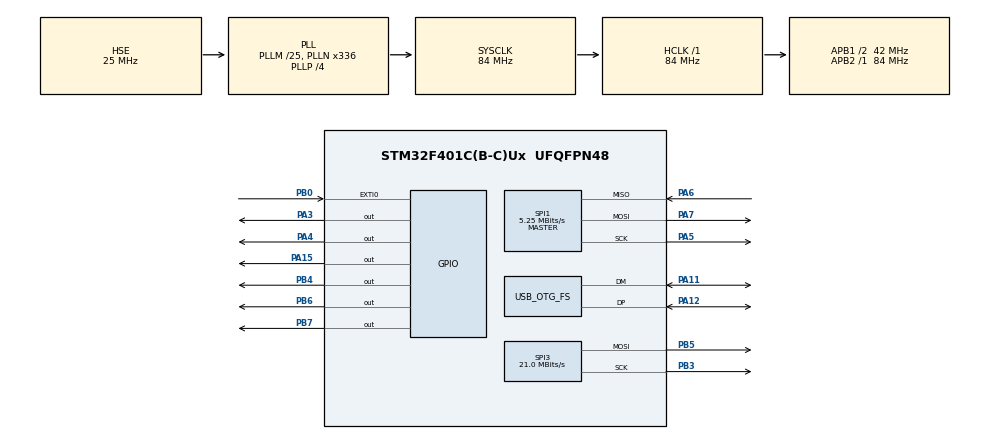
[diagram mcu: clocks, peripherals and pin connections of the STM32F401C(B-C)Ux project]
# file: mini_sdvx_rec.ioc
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AL94.I-CUBE-USBD-COMPOSITE.1.0.3.CompositeCcUSBJjCOMPOSITEJjCDCIiACM=true
AL94.I-CUBE-USBD-COMPOSITE.1.0.3.CompositeCcUSBJjCOMPOSITEJjCOMPOSITE=true
AL94.I-CUBE-USBD-COMPOSITE.1.0.3.CompositeCcUSBJjCOMPOSITEJjCore=true
AL94.I-CUBE-USBD-COMPOSITE.1.0.3.CompositeCcUSBJjCOMPOSITEJjHIDIiKEYBOARD=true
AL94.I-CUBE-USBD-COMPOSITE.1.0.3.CompositeCcUSBJjCOMPOSITEJjHIDIiMOUSE=true
AL94.I-CUBE-USBD-COMPOSITE.1.0.3._USBD_USE_CDC_ACM=true
AL94.I-CUBE-USBD-COMPOSITE.1.0.3._USBD_USE_DFU=false
AL94.I-CUBE-USBD-COMPOSITE.1.0.3._USBD_USE_HID_KEYBOARD=true
AL94.I-CUBE-USBD-COMPOSITE.1.0.3._USBD_USE_HID_MOUSE=true
AL94.I-CUBE-USBD-COMPOSITE.1.0.3._USBD_USE_HS=false
Mcu.Family=STM32F4
Mcu.Name=STM32F401C(B-C)Ux
Mcu.Package=UFQFPN48
NVIC.EXTI0_IRQn=true\:0\:0\:false\:false\:true\:true\:true\:true
NVIC.OTG_FS_IRQn=true\:0\:0\:false\:false\:true\:true\:true\:true
NVIC.PriorityGroup=NVIC_PRIORITYGROUP_4
PA11.Mode=Device_Only
PA11.Signal=USB_OTG_FS_DM
PA12.Mode=Device_Only
PA12.Signal=USB_OTG_FS_DP
PA13.Mode=Serial_Wire
PA13.Signal=SYS_JTMS-SWDIO
PA14.Mode=Serial_Wire
PA14.Signal=SYS_JTCK-SWCLK
PA15.Signal=GPIO_Output
PA3.GPIO_Speed=GPIO_SPEED_FREQ_HIGH
PA3.Signal=GPIO_Output
PA4.GPIO_Speed=GPIO_SPEED_FREQ_HIGH
PA4.PinState=GPIO_PIN_SET
PA4.Signal=GPIO_Output
PA5.Mode=Full_Duplex_Master
PA5.Signal=SPI1_SCK
PA6.Mode=Full_Duplex_Master
PA6.Signal=SPI1_MISO
PA7.Mode=Full_Duplex_Master
PA7.Signal=SPI1_MOSI
PB0.GPIO_ModeDefaultEXTI=GPIO_MODE_IT_FALLING
PB0.GPIO_PuPd=GPIO_PULLUP
PB0.Signal=GPXTI0
PB3.Mode=TX_Only_Simplex_Unidirect_Master
PB3.Signal=SPI3_SCK
PB4.Signal=GPIO_Output
PB5.Mode=TX_Only_Simplex_Unidirect_Master
PB5.Signal=SPI3_MOSI
PB6.Signal=GPIO_Output
PB7.Signal=GPIO_Output
PH0\ -\ OSC_IN.Mode=HSE-External-Oscillator
PH0\ -\ OSC_IN.Signal=RCC_OSC_IN
PH1\ -\ OSC_OUT.Mode=HSE-External-Oscillator
PH1\ -\ OSC_OUT.Signal=RCC_OSC_OUT
ProjectManager.HeapSize=0x400
ProjectManager.StackSize=0x600
ProjectManager.TargetToolchain=MDK-ARM V5.32
RCC.48MHZClocksFreq_Value=48000000
RCC.AHBFreq_Value=84000000
RCC.APB1CLKDivider=RCC_HCLK_DIV2
RCC.APB1Freq_Value=42000000
RCC.APB1TimFreq_Value=84000000
RCC.APB2Freq_Value=84000000
RCC.APB2TimFreq_Value=84000000
RCC.CortexFreq_Value=84000000
RCC.HCLKFreq_Value=84000000
RCC.HSE_VALUE=25000000
RCC.HSI_VALUE=16000000
RCC.LSE_VALUE=32768
RCC.PLLM=25
RCC.PLLN=336
RCC.PLLP=RCC_PLLP_DIV4
RCC.PLLQ=7
RCC.SYSCLKFreq_VALUE=84000000
RCC.SYSCLKSource=RCC_SYSCLKSOURCE_PLLCLK
RCC.VCOOutputFreq_Value=336000000
SPI1.BaudRatePrescaler=SPI_BAUDRATEPRESCALER_16
SPI1.CalculateBaudRate=5.25 MBits/s
SPI1.Direction=SPI_DIRECTION_2LINES
SPI1.Mode=SPI_MODE_MASTER
SPI1.VirtualType=VM_MASTER
SPI3.CalculateBaudRate=21.0 MBits/s
SPI3.Direction=SPI_DIRECTION_2LINES
SPI3.Mode=SPI_MODE_MASTER
SPI3.VirtualType=VM_MASTER
USB_OTG_FS.VirtualMode=Device_Only
VP_AL94.I-CUBE-USBD-COMPOSITE_VS_USBJjComposite_1.0.0_1.0.3.Mode=USBJjComposite
board=custom

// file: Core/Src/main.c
/* USER CODE BEGIN Header */
/**
 ******************************************************************************
 * @file           : main.c
 * @brief          : Main program body
 ******************************************************************************
 * @attention
 *
 * Copyright (c) 2023 STMicroelectronics.
 * All rights reserved.
 *
 * This software is licensed under terms that can be found in the LICENSE file
 * in the root directory of this software component.
 * If no LICENSE file comes with this software, it is provided AS-IS.
 *
 ******************************************************************************
 */
/* USER CODE END Header */
#include "main.h"
#include "spi.h"
#include "usb_otg.h"
#include "gpio.h"

/* USER CODE BEGIN Includes */
#include "lcd.h"
#include "nrf24l01.h"

/* USER CODE END Includes */

/* USER CODE BEGIN PV */
uint8_t tx_data[NRF24L01P_PAYLOAD_LENGTH] = {0, 1, 2, 3, 4, 5, 6, 7};
/* USER CODE END PV */

void SystemClock_Config(void);

int main(void)
{

  /* MCU Configuration--------------------------------------------------------*/

  /* Reset of all peripherals, Initializes the Flash interface and the Systick. */
  HAL_Init();

  /* Configure the system clock */
  SystemClock_Config();

  /* Initialize all configured peripherals */
  MX_GPIO_Init();
  MX_SPI1_Init();
  MX_SPI3_Init();
  MX_USB_OTG_FS_PCD_Init();
  /* USER CODE BEGIN 2 */

  // ? 初始化usb composite
  //  MX_USB_DEVICE_Init();
  // LCD_Init();
  nrf24l01p_tx_init(2500, _1Mbps);

  /* USER CODE END 2 */

  /* Infinite loop */
  while (1)
  {
    // change tx datas
    for (int i = 0; i < 8; i++)
      tx_data[i]++;

    // transmit
    nrf24l01p_tx_transmit(tx_data);
    HAL_Delay(500);
    HAL_GPIO_TogglePin(LCD_K_PORT, LCD_K_PIN);

  }
}

void SystemClock_Config(void)
{
  RCC_OscInitTypeDef RCC_OscInitStruct = {0};
  RCC_ClkInitTypeDef RCC_ClkInitStruct = {0};

  /** Configure the main internal regulator output voltage
   */
  __HAL_RCC_PWR_CLK_ENABLE();
  __HAL_PWR_VOLTAGESCALING_CONFIG(PWR_REGULATOR_VOLTAGE_SCALE2);

  /** Initializes the RCC Oscillators according to the specified parameters
   * in the RCC_OscInitTypeDef structure.
   */
  RCC_OscInitStruct.OscillatorType = RCC_OSCILLATORTYPE_HSE;
  RCC_OscInitStruct.HSEState = RCC_HSE_ON;
  RCC_OscInitStruct.PLL.PLLState = RCC_PLL_ON;
  RCC_OscInitStruct.PLL.PLLSource = RCC_PLLSOURCE_HSE;
  RCC_OscInitStruct.PLL.PLLM = 25;
  RCC_OscInitStruct.PLL.PLLN = 336;
  RCC_OscInitStruct.PLL.PLLP = RCC_PLLP_DIV4;
  RCC_OscInitStruct.PLL.PLLQ = 7;
  if (HAL_RCC_OscConfig(&RCC_OscInitStruct) != HAL_OK)
  {
    Error_Handler();
  }

  /** Initializes the CPU, AHB and APB buses clocks
   */
  RCC_ClkInitStruct.ClockType = RCC_CLOCKTYPE_HCLK | RCC_CLOCKTYPE_SYSCLK | RCC_CLOCKTYPE_PCLK1 | RCC_CLOCKTYPE_PCLK2;
  RCC_ClkInitStruct.SYSCLKSource = RCC_SYSCLKSOURCE_PLLCLK;
  RCC_ClkInitStruct.AHBCLKDivider = RCC_SYSCLK_DIV1;
  RCC_ClkInitStruct.APB1CLKDivider = RCC_HCLK_DIV2;
  RCC_ClkInitStruct.APB2CLKDivider = RCC_HCLK_DIV1;

  if (HAL_RCC_ClockConfig(&RCC_ClkInitStruct, FLASH_LATENCY_2) != HAL_OK)
  {
    Error_Handler();
  }
}

void Error_Handler(void)
{
  __disable_irq();
  while (1)
  {
  }
}
